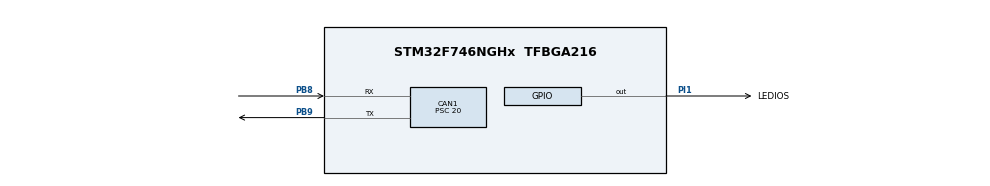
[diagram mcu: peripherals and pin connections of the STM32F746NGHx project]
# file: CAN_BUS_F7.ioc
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CAN1.BS1=CAN_BS1_2TQ
CAN1.CalculateBaudRate=500000
CAN1.CalculateTimeBit=2000
CAN1.CalculateTimeQuantum=500.0
CAN1.Prescaler=20
Mcu.Family=STM32F7
Mcu.Name=STM32F746NGHx
Mcu.Package=TFBGA216
NVIC.CAN1_RX0_IRQn=true\:0\:0\:false\:false\:true\:true\:true\:true
NVIC.PriorityGroup=NVIC_PRIORITYGROUP_4
PB8.GPIO_PuPd=GPIO_PULLUP
PB8.Mode=CAN_Activate
PB8.Signal=CAN1_RX
PB9.Mode=CAN_Activate
PB9.Signal=CAN1_TX
PI1.GPIO_Label=LEDIOS
PI1.Signal=GPIO_Output
ProjectManager.HeapSize=0x200
ProjectManager.StackSize=0x400
ProjectManager.TargetToolchain=STM32CubeIDE
RCC.AHBFreq_Value=80000000
RCC.APB1CLKDivider=RCC_HCLK_DIV2
RCC.APB1Freq_Value=40000000
RCC.APB1TimFreq_Value=80000000
RCC.APB2Freq_Value=80000000
RCC.APB2TimFreq_Value=80000000
RCC.CortexFreq_Value=80000000
RCC.HCLKFreq_Value=80000000
RCC.HSE_VALUE=25000000
RCC.HSI_VALUE=16000000
RCC.LSE_VALUE=32768
RCC.PLLM=8
RCC.PLLN=80
RCC.SYSCLKFreq_VALUE=80000000
RCC.SYSCLKSource=RCC_SYSCLKSOURCE_PLLCLK
RCC.USBFreq_Value=80000000
RCC.VCOOutputFreq_Value=160000000
board=custom

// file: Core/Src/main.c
/* USER CODE BEGIN Header */
/**
  ******************************************************************************
  * @file           : main.c
  * @brief          : Main program body
  ******************************************************************************
  * @attention
  *
  * Copyright (c) 2024 STMicroelectronics.
  * All rights reserved.
  *
  * This software is licensed under terms that can be found in the LICENSE file
  * in the root directory of this software component.
  * If no LICENSE file comes with this software, it is provided AS-IS.
  *
  ******************************************************************************
  */
/* USER CODE END Header */
#include "main.h"

CAN_HandleTypeDef hcan1;

void SystemClock_Config(void);
static void MPU_Config(void);
static void MX_GPIO_Init(void);
static void MX_CAN1_Init(void);

/* USER CODE BEGIN 0 */
uint16_t id_flag = 0;

CAN_TxHeaderTypeDef TxHeader;
CAN_RxHeaderTypeDef RxHeader;

uint32_t TxMailbox;

uint8_t TxData[8];
uint8_t RxData[8];

void HAL_CAN_RxFifo0MsgPendingCallback(CAN_HandleTypeDef *hcan){
  	HAL_CAN_GetRxMessage(hcan, CAN_RX_FIFO0, &RxHeader, RxData);
  	id_flag = RxHeader.StdId;
}

/* USER CODE END 0 */

int main(void)
{

  /* MPU Configuration--------------------------------------------------------*/
  MPU_Config();

  /* MCU Configuration--------------------------------------------------------*/

  /* Reset of all peripherals, Initializes the Flash interface and the Systick. */
  HAL_Init();

  /* Configure the system clock */
  SystemClock_Config();

  /* Initialize all configured peripherals */
  MX_GPIO_Init();
  MX_CAN1_Init();

  /* Infinite loop */
  /* USER CODE BEGIN WHILE */
  HAL_CAN_Start(&hcan1);
  HAL_CAN_ActivateNotification(&hcan1, CAN_IT_RX_FIFO0_MSG_PENDING);

	TxHeader.DLC = 2;
	TxHeader.IDE = CAN_ID_STD;
	TxHeader.RTR = CAN_RTR_DATA;

	HAL_GPIO_WritePin(LEDIOS_GPIO_Port, LEDIOS_Pin, 1);
	TxHeader.DLC = 1;
	TxData[0] = 10;
	TxHeader.StdId = 0x101;
//	HAL_CAN_AddTxMessage(&hcan1, &TxHeader, TxData, &TxMailbox);
	uint8_t counter = 0;
  while (1){
  	if(id_flag == 0x101 && RxData[0] == 11){
			TxHeader.DLC = 1;
			++counter;
			TxData[0] = counter;
			TxHeader.StdId = 0x101;
			HAL_CAN_AddTxMessage(&hcan1, &TxHeader, TxData, &TxMailbox);
			id_flag = 0;
		}
		else if(id_flag == 0x102){
			for(int i = 0; i < RxData[1] * 2; ++i){
				HAL_GPIO_TogglePin(LEDIOS_GPIO_Port, LEDIOS_Pin);
				HAL_Delay(RxData[0] * 250);
				id_flag = 0;
			}
		}
    /* USER CODE END WHILE */

  }
}

void SystemClock_Config(void)
{
  LL_FLASH_SetLatency(LL_FLASH_LATENCY_2);
  while(LL_FLASH_GetLatency()!= LL_FLASH_LATENCY_2)
  {
  }
  LL_PWR_SetRegulVoltageScaling(LL_PWR_REGU_VOLTAGE_SCALE3);
  LL_PWR_DisableOverDriveMode();
  LL_RCC_HSI_SetCalibTrimming(16);
  LL_RCC_HSI_Enable();

   /* Wait till HSI is ready */
  while(LL_RCC_HSI_IsReady() != 1)
  {

  }
  LL_RCC_PLL_ConfigDomain_SYS(LL_RCC_PLLSOURCE_HSI, LL_RCC_PLLM_DIV_8, 80, LL_RCC_PLLP_DIV_2);
  LL_RCC_PLL_Enable();

   /* Wait till PLL is ready */
  while(LL_RCC_PLL_IsReady() != 1)
  {

  }
  while (LL_PWR_IsActiveFlag_VOS() == 0)
  {
  }
  LL_RCC_SetAHBPrescaler(LL_RCC_SYSCLK_DIV_1);
  LL_RCC_SetAPB1Prescaler(LL_RCC_APB1_DIV_2);
  LL_RCC_SetAPB2Prescaler(LL_RCC_APB2_DIV_1);
  LL_RCC_SetSysClkSource(LL_RCC_SYS_CLKSOURCE_PLL);

   /* Wait till System clock is ready */
  while(LL_RCC_GetSysClkSource() != LL_RCC_SYS_CLKSOURCE_STATUS_PLL)
  {

  }
  LL_SetSystemCoreClock(80000000);

   /* Update the time base */
  if (HAL_InitTick (TICK_INT_PRIORITY) != HAL_OK)
  {
    Error_Handler();
  }
}

static void MX_CAN1_Init(void)
{

  hcan1.Instance = CAN1;
  hcan1.Init.Prescaler = 20;
  hcan1.Init.Mode = CAN_MODE_NORMAL;
  hcan1.Init.SyncJumpWidth = CAN_SJW_1TQ;
  hcan1.Init.TimeSeg1 = CAN_BS1_2TQ;
  hcan1.Init.TimeSeg2 = CAN_BS2_1TQ;
  hcan1.Init.TimeTriggeredMode = DISABLE;
  hcan1.Init.AutoBusOff = DISABLE;
  hcan1.Init.AutoWakeUp = DISABLE;
  hcan1.Init.AutoRetransmission = DISABLE;
  hcan1.Init.ReceiveFifoLocked = DISABLE;
  hcan1.Init.TransmitFifoPriority = DISABLE;
  if (HAL_CAN_Init(&hcan1) != HAL_OK)
  {
    Error_Handler();
  }
  /* USER CODE BEGIN CAN1_Init 2 */
  CAN_FilterTypeDef canfilterconfig;

	canfilterconfig.FilterActivation = CAN_FILTER_ENABLE;
	canfilterconfig.FilterBank = 10;  // anything between 0 to SlaveStartFilterBank
	canfilterconfig.FilterFIFOAssignment = CAN_RX_FIFO0;
	canfilterconfig.FilterIdHigh = 0x100 << 5;
	canfilterconfig.FilterIdLow = 0x0000;
	canfilterconfig.FilterMaskIdHigh = 0x100 << 5;
	canfilterconfig.FilterMaskIdLow = 0x0000;
	canfilterconfig.FilterMode = CAN_FILTERMODE_IDMASK;
	canfilterconfig.FilterScale = CAN_FILTERSCALE_32BIT;
	canfilterconfig.SlaveStartFilterBank = 13;  // 13 to 27 are assigned to slave CAN (CAN 2) OR 0 to 12 are assgned to CAN1

	HAL_CAN_ConfigFilter(&hcan1, &canfilterconfig);
  /* USER CODE END CAN1_Init 2 */

}

static void MX_GPIO_Init(void)
{
  LL_GPIO_InitTypeDef GPIO_InitStruct = {0};

  /* GPIO Ports Clock Enable */
  LL_AHB1_GRP1_EnableClock(LL_AHB1_GRP1_PERIPH_GPIOB);
  LL_AHB1_GRP1_EnableClock(LL_AHB1_GRP1_PERIPH_GPIOI);

  /**/
  LL_GPIO_ResetOutputPin(LEDIOS_GPIO_Port, LEDIOS_Pin);

  /**/
  GPIO_InitStruct.Pin = LEDIOS_Pin;
  GPIO_InitStruct.Mode = LL_GPIO_MODE_OUTPUT;
  GPIO_InitStruct.Speed = LL_GPIO_SPEED_FREQ_LOW;
  GPIO_InitStruct.OutputType = LL_GPIO_OUTPUT_PUSHPULL;
  GPIO_InitStruct.Pull = LL_GPIO_PULL_NO;
  LL_GPIO_Init(LEDIOS_GPIO_Port, &GPIO_InitStruct);

}

/* MPU Configuration */

void MPU_Config(void)
{
  MPU_Region_InitTypeDef MPU_InitStruct = {0};

  /* Disables the MPU */
  HAL_MPU_Disable();

  /** Initializes and configures the Region and the memory to be protected
  */
  MPU_InitStruct.Enable = MPU_REGION_ENABLE;
  MPU_InitStruct.Number = MPU_REGION_NUMBER0;
  MPU_InitStruct.BaseAddress = 0x0;
  MPU_InitStruct.Size = MPU_REGION_SIZE_4GB;
  MPU_InitStruct.SubRegionDisable = 0x87;
  MPU_InitStruct.TypeExtField = MPU_TEX_LEVEL0;
  MPU_InitStruct.AccessPermission = MPU_REGION_NO_ACCESS;
  MPU_InitStruct.DisableExec = MPU_INSTRUCTION_ACCESS_DISABLE;
  MPU_InitStruct.IsShareable = MPU_ACCESS_SHAREABLE;
  MPU_InitStruct.IsCacheable = MPU_ACCESS_NOT_CACHEABLE;
  MPU_InitStruct.IsBufferable = MPU_ACCESS_NOT_BUFFERABLE;

  HAL_MPU_ConfigRegion(&MPU_InitStruct);
  /* Enables the MPU */
  HAL_MPU_Enable(MPU_PRIVILEGED_DEFAULT);

}

void Error_Handler(void)
{
  __disable_irq();
  while (1)
  {
  }
}
